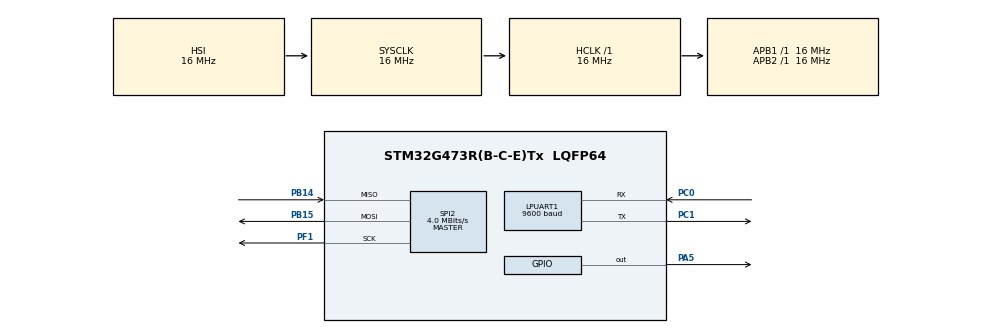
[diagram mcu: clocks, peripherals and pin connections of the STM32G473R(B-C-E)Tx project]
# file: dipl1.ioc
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Dma.LPUART1_RX.0.Direction=DMA_PERIPH_TO_MEMORY
Dma.LPUART1_RX.0.EventEnable=DISABLE
Dma.LPUART1_RX.0.Instance=DMA1_Channel1
Dma.LPUART1_RX.0.MemDataAlignment=DMA_MDATAALIGN_BYTE
Dma.LPUART1_RX.0.MemInc=DMA_MINC_ENABLE
Dma.LPUART1_RX.0.Mode=DMA_NORMAL
Dma.LPUART1_RX.0.PeriphDataAlignment=DMA_PDATAALIGN_BYTE
Dma.LPUART1_RX.0.PeriphInc=DMA_PINC_DISABLE
Dma.LPUART1_RX.0.Polarity=HAL_DMAMUX_REQ_GEN_RISING
Dma.LPUART1_RX.0.Priority=DMA_PRIORITY_LOW
Dma.LPUART1_RX.0.RequestNumber=1
Dma.LPUART1_RX.0.SignalID=NONE
Dma.LPUART1_RX.0.SyncEnable=DISABLE
Dma.LPUART1_RX.0.SyncPolarity=HAL_DMAMUX_SYNC_NO_EVENT
Dma.LPUART1_RX.0.SyncRequestNumber=1
Dma.LPUART1_RX.0.SyncSignalID=NONE
Dma.LPUART1_TX.1.Direction=DMA_MEMORY_TO_PERIPH
Dma.LPUART1_TX.1.EventEnable=DISABLE
Dma.LPUART1_TX.1.Instance=DMA1_Channel2
Dma.LPUART1_TX.1.MemDataAlignment=DMA_MDATAALIGN_BYTE
Dma.LPUART1_TX.1.MemInc=DMA_MINC_ENABLE
Dma.LPUART1_TX.1.Mode=DMA_NORMAL
Dma.LPUART1_TX.1.PeriphDataAlignment=DMA_PDATAALIGN_BYTE
Dma.LPUART1_TX.1.PeriphInc=DMA_PINC_DISABLE
Dma.LPUART1_TX.1.Polarity=HAL_DMAMUX_REQ_GEN_RISING
Dma.LPUART1_TX.1.Priority=DMA_PRIORITY_LOW
Dma.LPUART1_TX.1.RequestNumber=1
Dma.LPUART1_TX.1.SignalID=NONE
Dma.LPUART1_TX.1.SyncEnable=DISABLE
Dma.LPUART1_TX.1.SyncPolarity=HAL_DMAMUX_SYNC_NO_EVENT
Dma.LPUART1_TX.1.SyncRequestNumber=1
Dma.LPUART1_TX.1.SyncSignalID=NONE
Dma.Request0=LPUART1_RX
Dma.Request1=LPUART1_TX
Dma.Request2=SPI2_RX
Dma.Request3=SPI2_TX
Dma.SPI2_RX.2.Direction=DMA_PERIPH_TO_MEMORY
Dma.SPI2_RX.2.EventEnable=DISABLE
Dma.SPI2_RX.2.Instance=DMA1_Channel3
Dma.SPI2_RX.2.MemDataAlignment=DMA_MDATAALIGN_BYTE
Dma.SPI2_RX.2.MemInc=DMA_MINC_ENABLE
Dma.SPI2_RX.2.Mode=DMA_NORMAL
Dma.SPI2_RX.2.PeriphDataAlignment=DMA_PDATAALIGN_BYTE
Dma.SPI2_RX.2.PeriphInc=DMA_PINC_DISABLE
Dma.SPI2_RX.2.Polarity=HAL_DMAMUX_REQ_GEN_RISING
Dma.SPI2_RX.2.Priority=DMA_PRIORITY_LOW
Dma.SPI2_RX.2.RequestNumber=1
Dma.SPI2_RX.2.SignalID=NONE
Dma.SPI2_RX.2.SyncEnable=DISABLE
Dma.SPI2_RX.2.SyncPolarity=HAL_DMAMUX_SYNC_NO_EVENT
Dma.SPI2_RX.2.SyncRequestNumber=1
Dma.SPI2_RX.2.SyncSignalID=NONE
Dma.SPI2_TX.3.Direction=DMA_MEMORY_TO_PERIPH
Dma.SPI2_TX.3.EventEnable=DISABLE
Dma.SPI2_TX.3.Instance=DMA1_Channel4
Dma.SPI2_TX.3.MemDataAlignment=DMA_MDATAALIGN_BYTE
Dma.SPI2_TX.3.MemInc=DMA_MINC_ENABLE
Dma.SPI2_TX.3.Mode=DMA_NORMAL
Dma.SPI2_TX.3.PeriphDataAlignment=DMA_PDATAALIGN_BYTE
Dma.SPI2_TX.3.PeriphInc=DMA_PINC_DISABLE
Dma.SPI2_TX.3.Polarity=HAL_DMAMUX_REQ_GEN_RISING
Dma.SPI2_TX.3.Priority=DMA_PRIORITY_LOW
Dma.SPI2_TX.3.RequestNumber=1
Dma.SPI2_TX.3.SignalID=NONE
Dma.SPI2_TX.3.SyncEnable=DISABLE
Dma.SPI2_TX.3.SyncPolarity=HAL_DMAMUX_SYNC_NO_EVENT
Dma.SPI2_TX.3.SyncRequestNumber=1
Dma.SPI2_TX.3.SyncSignalID=NONE
FREERTOS.Tasks01=defaultTask,-3,1024,StartDefaultTask,Default,NULL,Dynamic,NULL,NULL
FREERTOS.configENABLE_FPU=1
FREERTOS.configMAX_TASK_NAME_LEN=30
FREERTOS.configTOTAL_HEAP_SIZE=24576
FREERTOS.configUSE_IDLE_HOOK=1
FREERTOS.configUSE_MALLOC_FAILED_HOOK=1
FREERTOS.configUSE_TICK_HOOK=1
LPUART1.BaudRate=9600
Mcu.Family=STM32G4
Mcu.Name=STM32G473R(B-C-E)Tx
Mcu.Package=LQFP64
NVIC.DMA1_Channel1_IRQn=true\:5\:0\:false\:false\:true\:true\:false\:true\:true
NVIC.DMA1_Channel2_IRQn=true\:5\:0\:false\:false\:true\:true\:false\:true\:true
NVIC.DMA1_Channel3_IRQn=true\:5\:0\:false\:false\:true\:true\:false\:true\:true
NVIC.DMA1_Channel4_IRQn=true\:5\:0\:false\:false\:true\:true\:false\:true\:true
NVIC.FPU_IRQn=true\:5\:0\:false\:false\:true\:true\:true\:false\:true
NVIC.LPUART1_IRQn=true\:5\:0\:false\:false\:true\:true\:false\:true\:true
NVIC.PriorityGroup=NVIC_PRIORITYGROUP_4
NVIC.SPI2_IRQn=true\:5\:0\:false\:false\:true\:true\:true\:true\:true
PA13.Mode=Serial_Wire
PA13.Signal=SYS_JTMS-SWDIO
PA14.Mode=Serial_Wire
PA14.Signal=SYS_JTCK-SWCLK
PA5.Signal=GPIO_Output
PB14.Mode=Full_Duplex_Master
PB14.Signal=SPI2_MISO
PB15.Mode=Full_Duplex_Master
PB15.Signal=SPI2_MOSI
PC0.GPIO_Speed=GPIO_SPEED_FREQ_HIGH
PC0.Mode=Asynchronous
PC0.Signal=LPUART1_RX
PC1.GPIO_Speed=GPIO_SPEED_FREQ_HIGH
PC1.Mode=Asynchronous
PC1.Signal=LPUART1_TX
PF1-OSC_OUT.Mode=Full_Duplex_Master
PF1-OSC_OUT.Signal=SPI2_SCK
ProjectManager.HeapSize=0x200
ProjectManager.StackSize=0x400
ProjectManager.TargetToolchain=STM32CubeIDE
RCC.ADC12Freq_Value=16000000
RCC.ADC345Freq_Value=16000000
RCC.AHBFreq_Value=16000000
RCC.APB1Freq_Value=16000000
RCC.APB1TimFreq_Value=16000000
RCC.APB2Freq_Value=16000000
RCC.APB2TimFreq_Value=16000000
RCC.CortexFreq_Value=16000000
RCC.EXTERNAL_CLOCK_VALUE=12288000
RCC.HCLKFreq_Value=16000000
RCC.HSE_VALUE=8000000
RCC.HSI48_VALUE=48000000
RCC.HSI_VALUE=16000000
RCC.LSE_VALUE=32768
RCC.SYSCLKFreq_VALUE=16000000
RCC.USBFreq_Value=64000000
RCC.VCOOutputFreq_Value=128000000
SPI2.BaudRatePrescaler=SPI_BAUDRATEPRESCALER_4
SPI2.CalculateBaudRate=4.0 MBits/s
SPI2.DataSize=SPI_DATASIZE_8BIT
SPI2.Direction=SPI_DIRECTION_2LINES
SPI2.Mode=SPI_MODE_MASTER
SPI2.VirtualType=VM_MASTER
VP_FREERTOS_VS_CMSIS_V1.Mode=CMSIS_V1
VP_SYS_VS_DBSignals.Mode=DisableDeadBatterySignals
board=custom

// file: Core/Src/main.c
/* USER CODE BEGIN Header */
/**
  ******************************************************************************
  * @file           : main.c
  * @brief          : Main program body
  ******************************************************************************
  * @attention
  *
  * Copyright (c) 2026 STMicroelectronics.
  * All rights reserved.
  *
  * This software is licensed under terms that can be found in the LICENSE file
  * in the root directory of this software component.
  * If no LICENSE file comes with this software, it is provided AS-IS.
  *
  ******************************************************************************
  */
/* USER CODE END Header */
#include "main.h"
#include "cmsis_os.h"

/* USER CODE BEGIN Includes */
#include "stdio.h"
#include <string.h>
/* USER CODE END Includes */

UART_HandleTypeDef hlpuart1;
DMA_HandleTypeDef hdma_lpuart1_rx;
DMA_HandleTypeDef hdma_lpuart1_tx;

SPI_HandleTypeDef hspi2;
DMA_HandleTypeDef hdma_spi2_rx;
DMA_HandleTypeDef hdma_spi2_tx;

osThreadId defaultTaskHandle;
/* USER CODE BEGIN PV */
char test[20] = "Hello UART!\r\n";

/* USER CODE END PV */

void SystemClock_Config(void);
static void MX_GPIO_Init(void);
static void MX_DMA_Init(void);
static void MX_LPUART1_UART_Init(void);
static void MX_SPI2_Init(void);
void StartDefaultTask(void const * argument);

int main(void)
{

  /* MCU Configuration--------------------------------------------------------*/

  /* Reset of all peripherals, Initializes the Flash interface and the Systick. */
  HAL_Init();

  /* Configure the system clock */
  SystemClock_Config();

  /* Initialize all configured peripherals */
  MX_GPIO_Init();
  MX_DMA_Init();
  MX_LPUART1_UART_Init();
  MX_SPI2_Init();

  /* USER CODE BEGIN RTOS_SEMAPHORES */
  /* add semaphores, ... */
  osSemaphoreId uartTxDoneSem;
  osSemaphoreDef(uartTxDone);
  uartTxDoneSem = osSemaphoreCreate(osSemaphore(uartTxDone), 1);
  osSemaphoreWait(uartTxDoneSem, osWaitForever); // разрешить первый запуск
  /* USER CODE END RTOS_SEMAPHORES */

  /* Create the thread(s) */
  /* definition and creation of defaultTask */
  osThreadDef(defaultTask, StartDefaultTask, osPriorityIdle, 0, 1024);
  defaultTaskHandle = osThreadCreate(osThread(defaultTask), NULL);

  /* Start scheduler */
  osKernelStart();

  /* We should never get here as control is now taken by the scheduler */

  /* Infinite loop */
  while (1)
  {

  }
}

void SystemClock_Config(void)
{
  RCC_OscInitTypeDef RCC_OscInitStruct = {0};
  RCC_ClkInitTypeDef RCC_ClkInitStruct = {0};

  /** Configure the main internal regulator output voltage
  */
  HAL_PWREx_ControlVoltageScaling(PWR_REGULATOR_VOLTAGE_SCALE1);

  /** Initializes the RCC Oscillators according to the specified parameters
  * in the RCC_OscInitTypeDef structure.
  */
  RCC_OscInitStruct.OscillatorType = RCC_OSCILLATORTYPE_HSI;
  RCC_OscInitStruct.HSIState = RCC_HSI_ON;
  RCC_OscInitStruct.HSICalibrationValue = RCC_HSICALIBRATION_DEFAULT;
  RCC_OscInitStruct.PLL.PLLState = RCC_PLL_NONE;
  if (HAL_RCC_OscConfig(&RCC_OscInitStruct) != HAL_OK)
  {
    Error_Handler();
  }

  /** Initializes the CPU, AHB and APB buses clocks
  */
  RCC_ClkInitStruct.ClockType = RCC_CLOCKTYPE_HCLK|RCC_CLOCKTYPE_SYSCLK
                              |RCC_CLOCKTYPE_PCLK1|RCC_CLOCKTYPE_PCLK2;
  RCC_ClkInitStruct.SYSCLKSource = RCC_SYSCLKSOURCE_HSI;
  RCC_ClkInitStruct.AHBCLKDivider = RCC_SYSCLK_DIV1;
  RCC_ClkInitStruct.APB1CLKDivider = RCC_HCLK_DIV1;
  RCC_ClkInitStruct.APB2CLKDivider = RCC_HCLK_DIV1;

  if (HAL_RCC_ClockConfig(&RCC_ClkInitStruct, FLASH_LATENCY_0) != HAL_OK)
  {
    Error_Handler();
  }
}

static void MX_LPUART1_UART_Init(void)
{

  /* USER CODE BEGIN LPUART1_Init 1 */
__HAL_RCC_LPUART1_CLK_ENABLE();

  /* USER CODE END LPUART1_Init 1 */
  hlpuart1.Instance = LPUART1;
  hlpuart1.Init.BaudRate = 9600;
  hlpuart1.Init.WordLength = UART_WORDLENGTH_8B;
  hlpuart1.Init.StopBits = UART_STOPBITS_1;
  hlpuart1.Init.Parity = UART_PARITY_NONE;
  hlpuart1.Init.Mode = UART_MODE_TX_RX;
  hlpuart1.Init.HwFlowCtl = UART_HWCONTROL_NONE;
  hlpuart1.Init.OneBitSampling = UART_ONE_BIT_SAMPLE_DISABLE;
  hlpuart1.Init.ClockPrescaler = UART_PRESCALER_DIV1;
  hlpuart1.AdvancedInit.AdvFeatureInit = UART_ADVFEATURE_NO_INIT;
  if (HAL_UART_Init(&hlpuart1) != HAL_OK)
  {
    Error_Handler();
  }
  if (HAL_UARTEx_SetTxFifoThreshold(&hlpuart1, UART_TXFIFO_THRESHOLD_1_8) != HAL_OK)
  {
    Error_Handler();
  }
  if (HAL_UARTEx_SetRxFifoThreshold(&hlpuart1, UART_RXFIFO_THRESHOLD_1_8) != HAL_OK)
  {
    Error_Handler();
  }
  if (HAL_UARTEx_DisableFifoMode(&hlpuart1) != HAL_OK)
  {
    Error_Handler();
  }

}

static void MX_SPI2_Init(void)
{

  /* SPI2 parameter configuration*/
  hspi2.Instance = SPI2;
  hspi2.Init.Mode = SPI_MODE_MASTER;
  hspi2.Init.Direction = SPI_DIRECTION_2LINES;
  hspi2.Init.DataSize = SPI_DATASIZE_8BIT;
  hspi2.Init.CLKPolarity = SPI_POLARITY_LOW;
  hspi2.Init.CLKPhase = SPI_PHASE_1EDGE;
  hspi2.Init.NSS = SPI_NSS_SOFT;
  hspi2.Init.BaudRatePrescaler = SPI_BAUDRATEPRESCALER_4;
  hspi2.Init.FirstBit = SPI_FIRSTBIT_MSB;
  hspi2.Init.TIMode = SPI_TIMODE_DISABLE;
  hspi2.Init.CRCCalculation = SPI_CRCCALCULATION_DISABLE;
  hspi2.Init.CRCPolynomial = 7;
  hspi2.Init.CRCLength = SPI_CRC_LENGTH_DATASIZE;
  hspi2.Init.NSSPMode = SPI_NSS_PULSE_ENABLE;
  if (HAL_SPI_Init(&hspi2) != HAL_OK)
  {
    Error_Handler();
  }

}

static void MX_DMA_Init(void)
{

  /* DMA controller clock enable */
  __HAL_RCC_DMAMUX1_CLK_ENABLE();
  __HAL_RCC_DMA1_CLK_ENABLE();

  /* DMA interrupt init */
  /* DMA1_Channel1_IRQn interrupt configuration */
  HAL_NVIC_SetPriority(DMA1_Channel1_IRQn, 5, 0);
  HAL_NVIC_EnableIRQ(DMA1_Channel1_IRQn);
  /* DMA1_Channel2_IRQn interrupt configuration */
  HAL_NVIC_SetPriority(DMA1_Channel2_IRQn, 5, 0);
  HAL_NVIC_EnableIRQ(DMA1_Channel2_IRQn);
  /* DMA1_Channel3_IRQn interrupt configuration */
  HAL_NVIC_SetPriority(DMA1_Channel3_IRQn, 5, 0);
  HAL_NVIC_EnableIRQ(DMA1_Channel3_IRQn);
  /* DMA1_Channel4_IRQn interrupt configuration */
  HAL_NVIC_SetPriority(DMA1_Channel4_IRQn, 5, 0);
  HAL_NVIC_EnableIRQ(DMA1_Channel4_IRQn);

}

static void MX_GPIO_Init(void)
{
  GPIO_InitTypeDef GPIO_InitStruct = {0};

  /* GPIO Ports Clock Enable */
  __HAL_RCC_GPIOF_CLK_ENABLE();
  __HAL_RCC_GPIOC_CLK_ENABLE();
  __HAL_RCC_GPIOA_CLK_ENABLE();
  __HAL_RCC_GPIOB_CLK_ENABLE();

  /*Configure GPIO pin Output Level */
  HAL_GPIO_WritePin(GPIOA, GPIO_PIN_5, GPIO_PIN_RESET);

  /*Configure GPIO pin : PA5 */
  GPIO_InitStruct.Pin = GPIO_PIN_5;
  GPIO_InitStruct.Mode = GPIO_MODE_OUTPUT_PP;
  GPIO_InitStruct.Pull = GPIO_NOPULL;
  GPIO_InitStruct.Speed = GPIO_SPEED_FREQ_LOW;
  HAL_GPIO_Init(GPIOA, &GPIO_InitStruct);

}

void StartDefaultTask(void const * argument)
{
  /* USER CODE BEGIN 5 */
  /* Infinite loop */
    const char msg[20] = "Hello UART!\r\n";
    for(;;) {
        HAL_UART_Transmit(&hlpuart1, (uint8_t*)msg, strlen(msg), HAL_MAX_DELAY);
        HAL_GPIO_TogglePin(GPIOA, GPIO_PIN_5);
        osDelay(500); // 500 мс, чтобы не засорять терминал
    }
  /* USER CODE END 5 */
}

void Error_Handler(void)
{
  __disable_irq();
  while (1)
  {
  }
}
